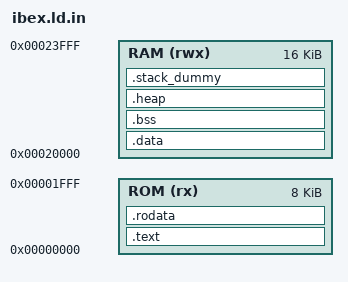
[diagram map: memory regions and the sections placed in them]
MEMORY
{
  ROM (rx)  : ORIGIN = 0x00000, LENGTH = 0x02000 /* 8 kB */
  RAM (rwx) : ORIGIN = 0x20000, LENGTH = 0x04000 /* 16 kB */
}

ENTRY(_start)

SECTIONS
{
  .text :
  {
    KEEP(*(.text.vectors))
    *(.text*)
    . = ALIGN(4);
    KEEP(*(.init))
    KEEP(*(.fini))

    . = ALIGN(4);
  } > ROM
  __etext = .;

  .rodata :
  {
    . = ALIGN(4);
    *(.rodata*)
    *(.srodata*)
    . = ALIGN(4);
  } > ROM

  __erodata = .;

  .data : AT (__erodata)
  {
    . = ALIGN(4);
    __data_start__ = .;
    *(.data*)
    __SDATA_BEGIN__ = .;
    *(.sdata*)
    *(.sdata .sdata.* .gnu.linkonce.s.*)

    __data_end__ = .;
  } > RAM

 
  .bss : AT (__erodata + SIZEOF(.data))
  {
    __bss_start__ = .;
    *(.sbss*)
    *(.bss*)
    *(COMMON)
    __bss_end__ = .;
  } > RAM

  .heap :
  {
    __end__ = .;
    _end = __end__;
    *(.heap*)
    __HeapLimit = .;
  } > RAM

  /* .stack_dummy section doesn't contains any symbols. It is only
   * used for linker to calculate size of stack sections, and assign
   * values to stack symbols later */
  .stack_dummy :
  {
    *(.stack)
  } > RAM

  /* Set stack top to end of RAM, and stack limit move down by
   * size of stack_dummy section */
  __StackTop = ORIGIN(RAM) + LENGTH(RAM);
  __StackTopInterrupt = ORIGIN(RAM) + LENGTH(RAM);

   __global_pointer$ = MIN(__SDATA_BEGIN__ + 0x800,
		            MAX(__data_start__ + 0x800, __bss_end__ - 0x800));

  PROVIDE(__stack = __StackTop);
  PROVIDE(__stack_int = __StackTopInterrupt);

  /* Check if data + heap + stack exceeds RAM limit */
  __StackLimit = __StackTop - SIZEOF(.stack_dummy);
  ASSERT(__StackLimit >= __HeapLimit, "region RAM overflowed with stack")
}
